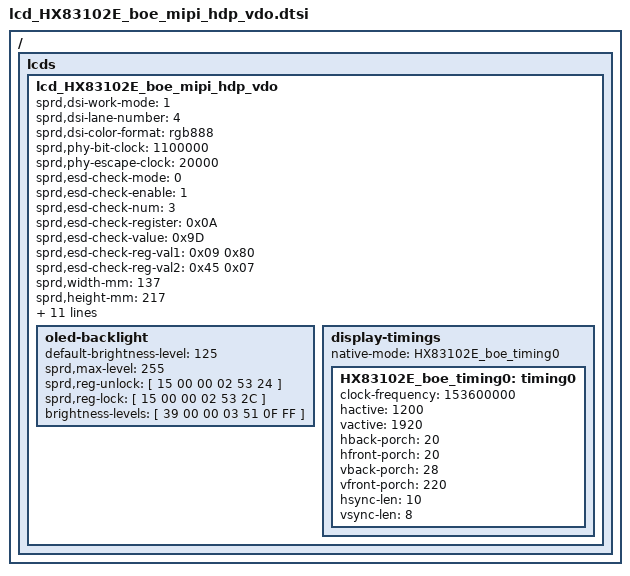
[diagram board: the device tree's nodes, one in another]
/ {
	fragment {
		target-path = "/";
		__overlay__ {
			lcds {
				lcd_HX83102E_boe_mipi_hdp_vdo: lcd_HX83102E_boe_mipi_hdp_vdo {

					sprd,dsi-work-mode = <1>; /* video burst mode*/
					sprd,dsi-lane-number = <4>;
					sprd,dsi-color-format = "rgb888";

					sprd,phy-bit-clock = <1100000>;	/* kbps */
					sprd,phy-escape-clock = <20000>;/* kHz */

					sprd,esd-check-mode = <0>;      /*read reg*/
					sprd,esd-check-enable = <1>;
					sprd,esd-check-num = <3>;
					sprd,esd-check-register = <0x0A>;
					sprd,esd-check-value = <0x9D>;
					sprd,esd-check-reg-val1 = <0x09 0x80>;//, <0x09 0x73>, <0x09 0x04>, <0x09 0x00>;
					sprd,esd-check-reg-val2 = <0x45 0x07>;

					sprd,width-mm = <137>;
					sprd,height-mm = <217>;

					sprd,reset-on-sequence = <0 1>, <1 60>;
					sprd,reset-off-sequence = <1 1>;

					sprd,use-dcs-write;

					sprd,initial-command = [
						/*----------------------LCD initial code start----------------------*/
			39 00 00 04 B9 83 10 2E
			39 00 00 12 B1 10 FA AF AF 27 27 B2 57 4D 36 36 36 36 22 21 15 00
			39 00 00 03 D2 27 27
			39 00 00 11 B2 00 B0 47 80 00 22 DC 2F 00 00 00 00 15 20 D7 00
			15 00 00 02 BD 03
			15 00 00 02 B2 80
			15 00 00 02 BD 00
			39 00 00 11 B4 A1 87 A1 87 A1 87 A1 87 01 92 01 58 00 FF 00 FF
			15 00 00 02 E9 CD
			15 00 00 02 BB 01
			15 00 00 02 E9 00
			39 00 00 09 BA 70 03 A8 83 F2 00 C0 0D
			39 00 00 04 BF FC 85 80
			39 00 00 0F C0 23 23 22 11 A2 1F 00 80 00 00 08 00 63 63
			15 00 00 02 C6 F9
			15 00 00 02 C7 30
			39 00 00 07 C8 00 04 04 00 00 82
			15 00 00 02 CC 0E
			39 00 00 04 D0 07 04 05
			39 00 00 05 D1 67 0C FF 05
			39 00 00 2C D3 00 00 00 00 01 04 00 10 0C 27 27 22 2F 1B 1B 04 04 32 10 19 00 19 32 17 B6 07 B6 32 10 1A 00 1A 00 00 00 35 01 55 1A 39 60 76 0F
			39 00 00 2D D5 03 02 03 02 01 00 01 00 21 20 21 20 23 22 23 22 18 18 18 18 18 18 18 18 05 04 05 04 07 06 07 06 19 19 19 19 38 38 38 38 18 18 18 18
			39 00 00 2D D6 04 05 04 05 06 07 06 07 22 23 22 23 20 21 20 21 38 38 38 38 18 18 18 18 02 03 02 03 00 01 00 01 19 19 19 19 18 18 18 18 18 18 18 18
			39 00 00 2F E0 00 02 09 0F 14 1E 35 3C 43 41 5A 5F 63 70 6C 73 7D 91 94 4B 54 63 73 00 02 09 0F 14 1E 35 3C 43 41 5A 5F 63 70 6C 73 7D 91 94 4B 54 63 73
			15 00 00 02 BD 01
			39 00 00 05 B1 01 9B 01 31
			39 00 00 0C D3 01 00 7C 00 00 11 10 00 0E 00 01
			15 00 00 02 BD 02
			39 00 00 07 B4 4E 00 33 11 33 88
			39 00 00 04 BF F2 00 02
			39 00 00 0D D8 FF FF FF FF FF F0 FF FF FF FF FF F0
			15 00 00 02 BD 03
			39 00 00 19 D8 AA AA AA AA AA A0 AA AA AA AA AA A0 55 55 55 55 55 50 55 55 55 55 55 50
			15 00 00 02 BD 00
			39 00 00 18 E7 12 13 02 02 46 46 0E 0E 19 21 27 77 1B 77 01 27 00 00 00 00 17 00 68
			15 00 00 02 BD 01
			39 00 00 08 E7 01 2C 01 8E 0D C6 0E
			15 00 00 02 BD 02
			39 00 00 1D E7 FF 01 FD 01 00 00 22 00 00 00 00 00 00 00 00 00 00 00 00 00 00 00 00 00 81 00 02 40
			15 00 00 02 BD 00
			39 00 00 03 E1 00 02
			39 00 00 03 51 00 00
			15 00 00 02 53 2C
			39 00 00 05 C9 00 0D F0 00 
			39 00 00 04 B9 55 66 77
			15 00 00 02 D9 02
			39 00 00 04 B9 83 10 2E
			05 3C 00 01 11
			39 00 00 11 B2 00 B0 47 80 00 22 DC 2F 00 00 00 00 15 20 D7 00
			05 14 00 01 29
						/*-------------  Display Initial Setting end -------------------------*/
					];

					sprd,sleep-in-command-without-gesture = [
						05 14 00 01 28
						05 32 00 01 10
						39 00 00 04 B9 83 10 2E
						15 00 00 02 B1 21
					];

					sprd,sleep-in-command-with-gesture = [
						05 14 00 01 28
						05 32 00 01 10
					];
					sprd,sleep-out-command = [
						05 78 00 01 11
						05 14 00 01 29
					];
					oled-backlight{
						default-brightness-level = <125>;
						sprd,max-level = <255>;

						sprd,reg-unlock = [
							15 00 00 02 53 24
						];

						sprd,reg-lock = [
							15 00 00 02 53 2C
						];

						brightness-levels = [
							39 00 00 03 51 0F FF
						];

					};
					display-timings {
						native-mode = <&HX83102E_boe_timing0>;

						HX83102E_boe_timing0: timing0 {
							clock-frequency = <153600000>;
							hactive = <1200>;
							vactive = <1920>;
							hback-porch = <20>;
							hfront-porch = <20>;
							vback-porch = <28>;
							vfront-porch = <220>;
							hsync-len = <10>;
							vsync-len = <8>;
						};
					};
				};
			};
		};
	};
};
